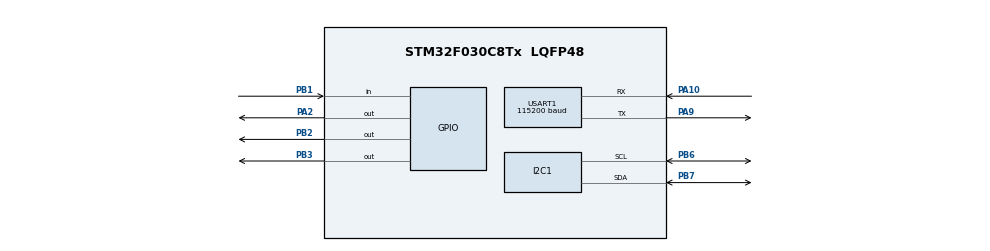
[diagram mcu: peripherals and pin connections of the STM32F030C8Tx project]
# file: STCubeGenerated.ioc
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FREERTOS.HEAP_NUMBER=2
FREERTOS.Tasks01=defaultTask,24,64,StartDefaultTask,Default,NULL,Dynamic,NULL,NULL;LEDOn,8,256,StartTask02,Default,NULL,Dynamic,NULL,NULL;LEDOff,8,64,StartTask03,Default,NULL,Dynamic,NULL,NULL
FREERTOS.configMINIMAL_STACK_SIZE=64
FREERTOS.configTOTAL_HEAP_SIZE=2048
Mcu.Family=STM32F0
Mcu.Name=STM32F030C8Tx
Mcu.Package=LQFP48
NVIC.TIM3_IRQn=true\:0\:0\:false\:false\:true\:false\:false\:true
NVIC.TimeBase=TIM3_IRQn
NVIC.TimeBaseIP=TIM3
PA10.Mode=Asynchronous
PA10.Signal=USART1_RX
PA13.Mode=Serial_Wire
PA13.Signal=SYS_SWDIO
PA14.Mode=Serial_Wire
PA14.Signal=SYS_SWCLK
PA2.Signal=GPIO_Output
PA9.Mode=Asynchronous
PA9.Signal=USART1_TX
PB1.Signal=GPIO_Input
PB2.Signal=GPIO_Output
PB3.Signal=GPIO_Output
PB6.Mode=I2C
PB6.Signal=I2C1_SCL
PB7.Mode=I2C
PB7.Signal=I2C1_SDA
ProjectManager.HeapSize=0x200
ProjectManager.StackSize=0x400
ProjectManager.TargetToolchain=MDK-ARM V5
USART1.BaudRate=115200
USART1.VirtualMode-Asynchronous=VM_ASYNC
VP_FREERTOS_VS_CMSIS_V2.Mode=CMSIS_V2
VP_SYS_VS_tim3.Mode=TIM3
board=custom

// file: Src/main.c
/* USER CODE BEGIN Header */
/**
  ******************************************************************************
  * @file           : main.c
  * @brief          : Main program body
  ******************************************************************************
  * @attention
  *
  * <h2><center>&copy; Copyright (c) 2021 STMicroelectronics.
  * All rights reserved.</center></h2>
  *
  * This software component is licensed by ST under Ultimate Liberty license
  * SLA0044, the "License"; You may not use this file except in compliance with
  * the License. You may obtain a copy of the License at:
  *                             www.st.com/SLA0044
  *
  ******************************************************************************
  */
/* USER CODE END Header */
#include "main.h"
#include "cmsis_os.h"
#include "i2c.h"
#include "usart.h"
#include "gpio.h"

/* USER CODE BEGIN Includes */

#include "mpu.h"
#include "max30102.h"

/* USER CODE END Includes */

void SystemClock_Config(void);
void MX_FREERTOS_Init(void);

int main(void)
{

  /* MCU Configuration--------------------------------------------------------*/

  /* Reset of all peripherals, Initializes the Flash interface and the Systick. */
  HAL_Init();

  /* Configure the system clock */
  SystemClock_Config();

  /* Initialize all configured peripherals */
  MX_GPIO_Init();
  MX_I2C1_Init();
  MX_USART1_UART_Init();
  /* USER CODE BEGIN 2 */
	MPU6050Init();
	//max30102_init();

  /* USER CODE END 2 */

  /* Init scheduler */
  osKernelInitialize();  /* Call init function for freertos objects (in freertos.c) */
  MX_FREERTOS_Init();
  /* Start scheduler */
  osKernelStart();

  /* We should never get here as control is now taken by the scheduler */
  /* Infinite loop */
  while (1)
  {

  }
}

void SystemClock_Config(void)
{
  RCC_OscInitTypeDef RCC_OscInitStruct = {0};
  RCC_ClkInitTypeDef RCC_ClkInitStruct = {0};
  RCC_PeriphCLKInitTypeDef PeriphClkInit = {0};

  /** Initializes the RCC Oscillators according to the specified parameters
  * in the RCC_OscInitTypeDef structure.
  */
  RCC_OscInitStruct.OscillatorType = RCC_OSCILLATORTYPE_HSI;
  RCC_OscInitStruct.HSIState = RCC_HSI_ON;
  RCC_OscInitStruct.HSICalibrationValue = RCC_HSICALIBRATION_DEFAULT;
  RCC_OscInitStruct.PLL.PLLState = RCC_PLL_NONE;
  if (HAL_RCC_OscConfig(&RCC_OscInitStruct) != HAL_OK)
  {
    Error_Handler();
  }
  /** Initializes the CPU, AHB and APB buses clocks
  */
  RCC_ClkInitStruct.ClockType = RCC_CLOCKTYPE_HCLK|RCC_CLOCKTYPE_SYSCLK
                              |RCC_CLOCKTYPE_PCLK1;
  RCC_ClkInitStruct.SYSCLKSource = RCC_SYSCLKSOURCE_HSI;
  RCC_ClkInitStruct.AHBCLKDivider = RCC_SYSCLK_DIV1;
  RCC_ClkInitStruct.APB1CLKDivider = RCC_HCLK_DIV1;

  if (HAL_RCC_ClockConfig(&RCC_ClkInitStruct, FLASH_LATENCY_0) != HAL_OK)
  {
    Error_Handler();
  }
  PeriphClkInit.PeriphClockSelection = RCC_PERIPHCLK_USART1|RCC_PERIPHCLK_I2C1;
  PeriphClkInit.Usart1ClockSelection = RCC_USART1CLKSOURCE_PCLK1;
  PeriphClkInit.I2c1ClockSelection = RCC_I2C1CLKSOURCE_HSI;
  if (HAL_RCCEx_PeriphCLKConfig(&PeriphClkInit) != HAL_OK)
  {
    Error_Handler();
  }
}

 /**
  * @brief  Period elapsed callback in non blocking mode
  * @note   This function is called  when TIM3 interrupt took place, inside
  * HAL_TIM_IRQHandler(). It makes a direct call to HAL_IncTick() to increment
  * a global variable "uwTick" used as application time base.
  * @param  htim : TIM handle
  * @retval None
  */
void HAL_TIM_PeriodElapsedCallback(TIM_HandleTypeDef *htim)
{
  if (htim->Instance == TIM3) {
    HAL_IncTick();
  }
}

void Error_Handler(void)
{
  __disable_irq();
  while (1)
  {
  }
}

/************************ (C) COPYRIGHT STMicroelectronics *****END OF FILE****/

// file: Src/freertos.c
/* USER CODE BEGIN Header */
/**
  ******************************************************************************
  * File Name          : freertos.c
  * Description        : Code for freertos applications
  ******************************************************************************
  * @attention
  *
  * <h2><center>&copy; Copyright (c) 2021 STMicroelectronics.
  * All rights reserved.</center></h2>
  *
  * This software component is licensed by ST under Ultimate Liberty license
  * SLA0044, the "License"; You may not use this file except in compliance with
  * the License. You may obtain a copy of the License at:
  *                             www.st.com/SLA0044
  *
  ******************************************************************************
  */
/* USER CODE END Header */

#include "FreeRTOS.h"
#include "task.h"
#include "main.h"
#include "cmsis_os.h"

/* USER CODE BEGIN Includes */

#include "mpu.h"
#include "max30102.h"
#include "usart.h"

/* USER CODE END Includes */

/* Definitions for defaultTask */
osThreadId_t defaultTaskHandle;
const osThreadAttr_t defaultTask_attributes = {
  .name = "defaultTask",
  .stack_size = 64 * 4,
  .priority = (osPriority_t) osPriorityNormal,
};
/* Definitions for LEDOn */
osThreadId_t LEDOnHandle;
const osThreadAttr_t LEDOn_attributes = {
  .name = "LEDOn",
  .stack_size = 256 * 4,
  .priority = (osPriority_t) osPriorityLow,
};
/* Definitions for LEDOff */
osThreadId_t LEDOffHandle;
const osThreadAttr_t LEDOff_attributes = {
  .name = "LEDOff",
  .stack_size = 64 * 4,
  .priority = (osPriority_t) osPriorityLow,
};

void StartDefaultTask(void *argument);
void StartTask02(void *argument);
void StartTask03(void *argument);

void MX_FREERTOS_Init(void); /* (MISRA C 2004 rule 8.1) */

void MX_FREERTOS_Init(void) {

  /* Create the thread(s) */
  /* creation of defaultTask */
  defaultTaskHandle = osThreadNew(StartDefaultTask, NULL, &defaultTask_attributes);

  /* creation of LEDOn */
  LEDOnHandle = osThreadNew(StartTask02, NULL, &LEDOn_attributes);

  /* creation of LEDOff */
  LEDOffHandle = osThreadNew(StartTask03, NULL, &LEDOff_attributes);

}

void StartDefaultTask(void *argument)
{
  /* USER CODE BEGIN StartDefaultTask */
  /* Infinite loop */
  for(;;)
  {
    osDelay(1000);
  }
  /* USER CODE END StartDefaultTask */
}

void StartTask02(void *argument)
{
  /* USER CODE BEGIN StartTask02 */
  /* Infinite loop */
  for(;;)
  {
	  MAX30100_InterruptHandler();
	  //max30102_getFIFO(&fifoData, max30102_getUnreadSampleCount());
	  //USARTPrintNumber(fifoData.iRed, "iRed: ");
	  //USARTPrintNumber(fifoData.red, "Red: ");
	  HAL_GPIO_WritePin(GPIOB, GPIO_PIN_2, GPIO_PIN_SET);
	  HAL_GPIO_WritePin(GPIOA, GPIO_PIN_2, GPIO_PIN_SET);
    osDelay(1000);
  }
  /* USER CODE END StartTask02 */
}

void StartTask03(void *argument)
{
  /* USER CODE BEGIN StartTask03 */
  /* Infinite loop */
  for(;;)
  {
	  HAL_GPIO_WritePin(GPIOB, GPIO_PIN_2, GPIO_PIN_RESET);
	  HAL_GPIO_WritePin(GPIOA, GPIO_PIN_2, GPIO_PIN_RESET);
    osDelay(1500);
  }
  /* USER CODE END StartTask03 */
}

/************************ (C) COPYRIGHT STMicroelectronics *****END OF FILE****/
